# HSR register map
Registers from a debugger description file.
Registers are 32-bit, access not given, no defined reset value unless marked. A register's access mark holds for its fields unless they carry their own. Addresses are absolute; registers are grouped by the start of their names; lines under a group give offsets from that group; [hi:lo] are bit positions; {n}, {i} and the like mark numbered series; 'fields as' and 'values as' point back to an identical list; <NAME> marks a mode.

## RCI
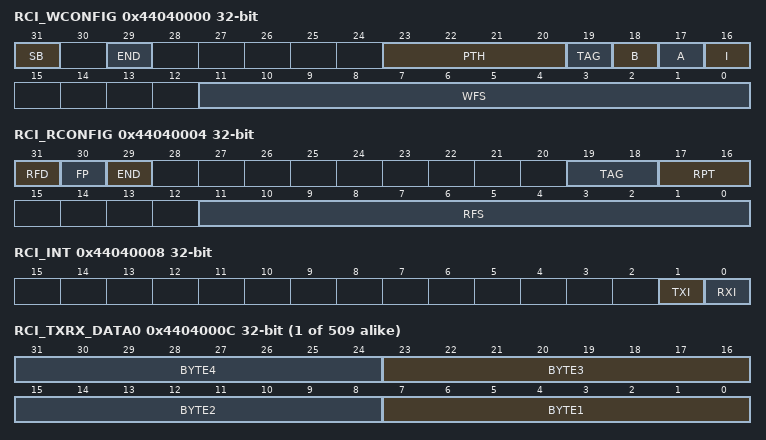
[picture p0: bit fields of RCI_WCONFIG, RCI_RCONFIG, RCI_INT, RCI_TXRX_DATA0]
0x44040000 RCI_WCONFIG
  [31] SB, [29] END, [23:20] PTH, [19] TAG, [18] B, [17] A, [16] I, [11:0] WFS
0x44040004 RCI_RCONFIG
  [31] RFD, [30] FP, [29] END, [19:18] TAG, [17:16] RPT, [11:0] RFS
0x44040008 RCI_INT ro
  [1] TXI, [0] RXI
{0x4404000C+4i} RCI_TXRX_DATA{i} (i=0..508)
  [8n-1:8n-8] BYTE{n} (n=1..4)

## R
0x44048000 R_MACADL
  [31:0] MAL
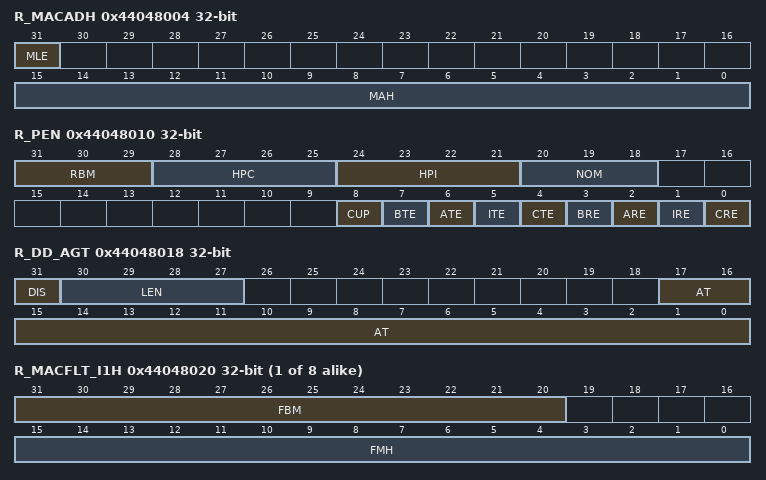
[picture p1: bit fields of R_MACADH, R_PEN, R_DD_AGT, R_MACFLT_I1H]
0x44048004 R_MACADH
  [31] MLE, [15:0] MAH
0x44048008 R_TST1 ro
  [31:0] TS1
0x4404800C R_TST2
  [31:0] TS2
0x44048010 R_PEN
  [31:29] RBM, [28:25] HPC, [24:21] HPI, [20:18] NOM, [8] CUP, [7] BTE, [6] ATE, [5] ITE, [4] CTE, [3] BRE, [2] ARE, [1] IRE, [0] CRE
0x44048014 R_PNT_AGT
  [15:0] AT
0x44048018 R_DD_AGT
  [31] DIS, [30:27] LEN, [17:0] AT
{0x44048014+8i} R_MACFLT_I{i}L (i=1..8)
  [31:0] FML
{0x44048018+8i} R_MACFLT_I{i}H (i=1..8)
  [31:20] FBM, [15:0] FMH
{0x44048054+8i} R_MACFLT_C{i}L (i=1..6)
  [31:0] FML
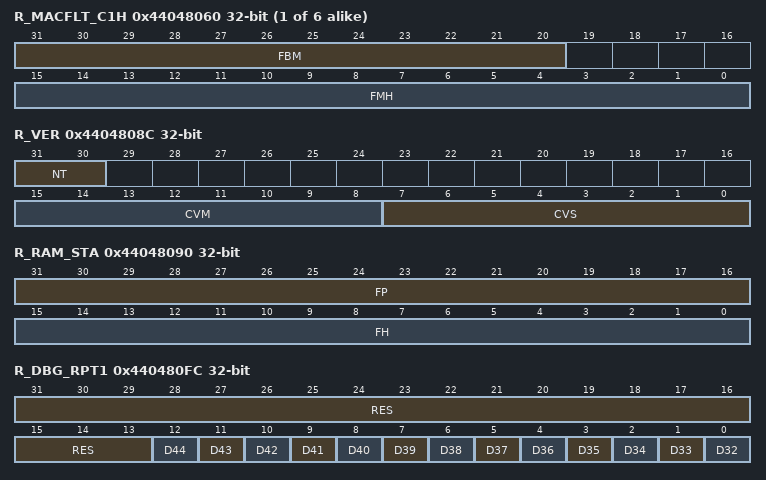
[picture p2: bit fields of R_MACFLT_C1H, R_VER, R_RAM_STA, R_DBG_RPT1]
{0x44048058+8i} R_MACFLT_C{i}H (i=1..6)
  [31:20] FBM, [15:0] FMH
0x4404808C R_VER ro
  [31:30] NT, [15:8] CVM, [7:0] CVS
0x44048090 R_RAM_STA ro
  [31:16] FP, [15:0] FH
0x44048094 R_UFMC ro
  [31:0] UF
0x44048098 R_FRA_ALL_ARX ro
  [31:0] ALL
0x4404809C R_FRA_TAG_ARX ro
  [31:0] TAG
0x440480A0 R_FRA_NLL_ARX ro
  [31:0] NLL
0x440480A4 R_FRA_ERR_ARX ro
  [31:0] ERR
0x440480A8 R_FRA_WRO_ARX ro
  [31:0] WRO
0x440480AC R_FRA_ALL_ATX ro
  [31:0] ALL
0x440480B0 R_FRA_TAG_ATX ro
  [31:0] TAG
0x440480B4 R_FRA_NLL_ATX ro
  [31:0] NLL
0x440480B8 R_FRA_ALL_BRX ro
  [31:0] ALL
0x440480BC R_FRA_TAG_BRX ro
  [31:0] TAG
0x440480C0 R_FRA_NLL_BRX ro
  [31:0] NLL
0x440480C4 R_FRA_ERR_BRX ro
  [31:0] ERR
0x440480C8 R_FRA_WRO_BRX ro
  [31:0] WRO
0x440480CC R_FRA_ALL_BTX ro
  [31:0] ALL
0x440480D0 R_FRA_TAG_BTX ro
  [31:0] TAG
0x440480D4 R_FRA_NLL_BTX ro
  [31:0] NLL
0x440480D8 R_FRA_ALL_CRX ro
  [31:0] ALL
0x440480DC R_FRA_TAG_CRX ro
  [31:0] TAG
0x440480E0 R_FRA_NLL_CRX ro
  [31:0] NLL
0x440480E4 R_FRA_ERR_CRX ro
  [31:0] ERR
0x440480E8 R_FRA_WRO_CRX ro
  [31:0] WRO
0x440480EC R_FRA_ALL_CTX ro
  [31:0] ALL
0x440480F0 R_FRA_TAG_CTX ro
  [31:0] TAG
0x440480F4 R_FRA_NLL_CTX ro
  [31:0] NLL
0x440480F8 R_FREE_FRA_M ro
  [31:0] FF
0x440480FC R_DBG_RPT1
  [31:13] RES, [n-32] D{n} (n=32..44)
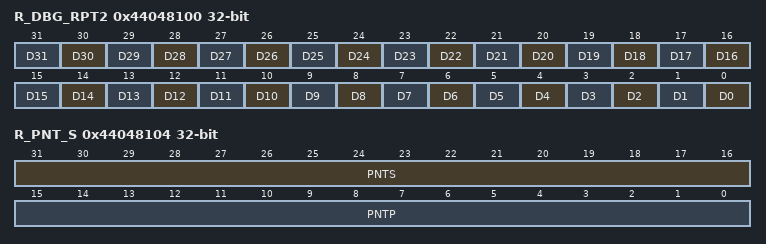
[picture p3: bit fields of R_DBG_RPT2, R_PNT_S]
0x44048100 R_DBG_RPT2
  [n] D{n} (n=0..31)
0x44048104 R_PNT_S ro
  [31:16] PNTS, [15:0] PNTP
0x44048108 R_PNT_D ro
  [31:0] DATA

## RPTP
0x4404C000 RPTP_ID ro
  [15:0] ID
0x4404C004 RPTP_TST
  [15:0] TST
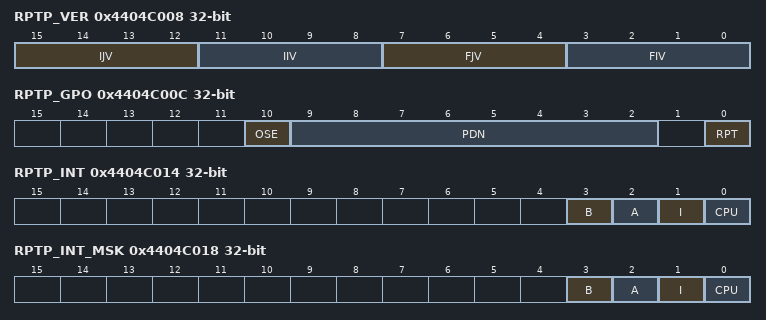
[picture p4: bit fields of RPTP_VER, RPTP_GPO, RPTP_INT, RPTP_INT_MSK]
0x4404C008 RPTP_VER ro
  [15:12] IJV, [11:8] IIV, [7:4] FJV, [3:0] FIV
0x4404C00C RPTP_GPO
  [10] OSE, [9:2] PDN, [0] RPT
0x4404C014 RPTP_INT ro
  [3] B, [2] A, [1] I, [0] CPU
0x4404C018 RPTP_INT_MSK
  [3] B, [2] A, [1] I, [0] CPU
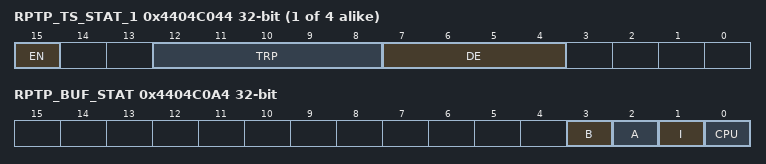
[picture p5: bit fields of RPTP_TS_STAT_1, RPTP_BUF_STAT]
{0x4404C02C+0x18*i} RPTP_TS_STAT_{i} (i=1..4)
  [15] EN, [12:8] TRP, [7:4] DE
{0x4404C030+0x18*i} RPTP_TS_RD_{i} ro (i=1..4)
  [15:0] TS
{0x4404C034+0x18*i} RPTP_PORT_CONF_{i} (i=1..4)
  [3:2] PDP
{0x4404C038+0x18*i} RPTP_P_DELAY_{i} (i=1..4)
  [15:0] PED
{0x4404C03C+0x18*i} RPTP_PHY_DLY_TX_{i} (i=1..4)
  [15:0] PDT
{0x4404C040+0x18*i} RPTP_PHY_DLY_RX_{i} (i=1..4)
  [15:0] PDR
0x4404C0A4 RPTP_BUF_STAT ro
  [3] B, [2] A, [1] I, [0] CPU
